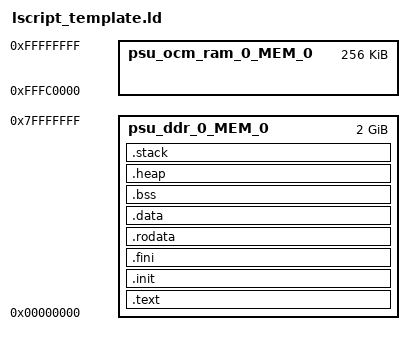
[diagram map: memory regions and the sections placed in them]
/*******************************************************************************
 * Linker Script for KV260 BRAM Test Application
 *
 * This is a template linker script. The actual linker script will be
 * auto-generated by Vitis based on the hardware platform.
 *
 * Memory Map (KV260 Zynq UltraScale+ MPSoC):
 *   - DDR: 0x00000000 - 0x7FFFFFFF (2GB, but may vary)
 *   - OCM: 0xFFFC0000 - 0xFFFFFFFF (256KB)
 *   - BRAM (PL): 0x80000000 - 0x80001FFF (8KB) - Our test target
 *
 * Note: This file is provided as reference. Vitis will generate the
 * actual linker script based on the XSA file.
 ******************************************************************************/

/* Entry Point */
ENTRY(_vector_table)

/* Memory Regions - Will be auto-populated by Vitis */
MEMORY
{
    psu_ddr_0_MEM_0 : ORIGIN = 0x0, LENGTH = 0x80000000
    psu_ocm_ram_0_MEM_0 : ORIGIN = 0xFFFC0000, LENGTH = 0x40000
    /* Note: BRAM at 0x80000000 is NOT used for code/data storage */
    /* It's our test peripheral accessed via Xil_In32/Xil_Out32 */
}

/* Stack and Heap Configuration */
_STACK_SIZE = DEFINED(_STACK_SIZE) ? _STACK_SIZE : 0x10000;  /* 64KB */
_HEAP_SIZE = DEFINED(_HEAP_SIZE) ? _HEAP_SIZE : 0x10000;     /* 64KB */

/* Section Definitions */
SECTIONS
{
    .text : {
        KEEP(*(.vectors))
        *(.boot)
        *(.text)
        *(.text.*)
        *(.gnu.linkonce.t.*)
        *(.plt)
        *(.gnu_warning)
        *(.gcc_except_table)
        *(.glue_7)
        *(.glue_7t)
        *(.ARM.extab)
        *(.gnu.hash)
    } > psu_ddr_0_MEM_0

    .init : {
        KEEP(*(.init))
    } > psu_ddr_0_MEM_0

    .fini : {
        KEEP(*(.fini))
    } > psu_ddr_0_MEM_0

    .rodata : {
        . = ALIGN(64);
        *(.rodata)
        *(.rodata.*)
        *(.gnu.linkonce.r.*)
    } > psu_ddr_0_MEM_0

    .data : {
        . = ALIGN(64);
        *(.data)
        *(.data.*)
        *(.gnu.linkonce.d.*)
    } > psu_ddr_0_MEM_0

    .bss : {
        . = ALIGN(64);
        __bss_start = .;
        *(.bss)
        *(.bss.*)
        *(.gnu.linkonce.b.*)
        *(COMMON)
        . = ALIGN(64);
        __bss_end = .;
    } > psu_ddr_0_MEM_0

    .heap : {
        . = ALIGN(64);
        _heap_start = .;
        . += _HEAP_SIZE;
        _heap_end = .;
    } > psu_ddr_0_MEM_0

    .stack : {
        . = ALIGN(64);
        _stack_end = .;
        . += _STACK_SIZE;
        . = ALIGN(64);
        _stack_start = .;
    } > psu_ddr_0_MEM_0
}
